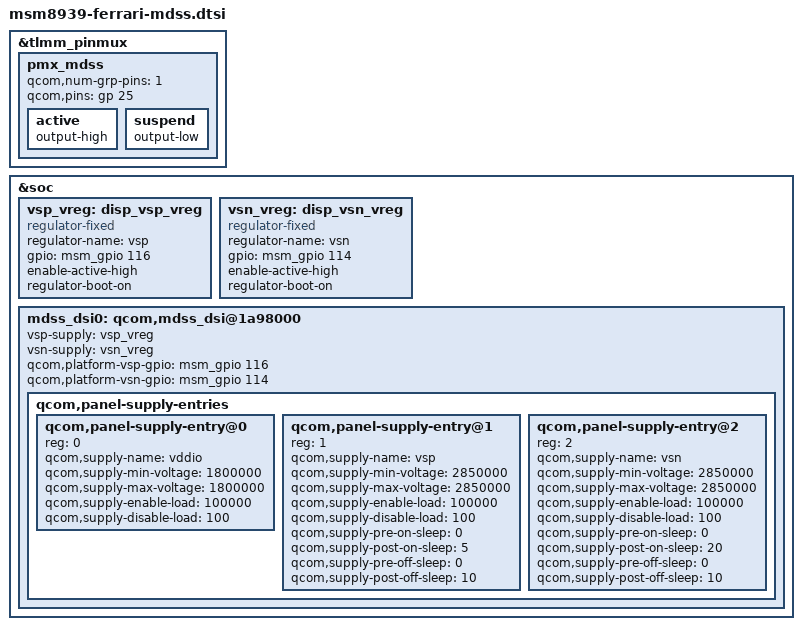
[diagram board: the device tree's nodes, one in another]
/* Copyright (c) 2014-2015, The Linux Foundation. All rights reserved.
 *
 * This program is free software; you can redistribute it and/or modify
 * it under the terms of the GNU General Public License version 2 and
 * only version 2 as published by the Free Software Foundation.
 *
 * This program is distributed in the hope that it will be useful,
 * but WITHOUT ANY WARRANTY; without even the implied warranty of
 * MERCHANTABILITY or FITNESS FOR A PARTICULAR PURPOSE.  See the
 * GNU General Public License for more details.
 */

&tlmm_pinmux {
	pmx_mdss: pmx_mdss {
		qcom,num-grp-pins = <1>;
		qcom,pins = <&gp 25>;

		/* revert ab9cf13bf5 */
		active {
			output-high;
		};
		suspend {
			output-low;
		};
	};
};

&soc {
	vsp_vreg: disp_vsp_vreg {
		compatible = "regulator-fixed";
		regulator-name = "vsp";
		gpio = <&msm_gpio 116 0>;
		enable-active-high;
		regulator-boot-on;
	};

	vsn_vreg: disp_vsn_vreg {
		compatible = "regulator-fixed";
		regulator-name = "vsn";
		gpio = <&msm_gpio 114 0>;
		enable-active-high;
		regulator-boot-on;
	};

	mdss_dsi0: qcom,mdss_dsi@1a98000 {
		/delete-property/ qcom,platform-enable-gpio;
		/delete-property/ qcom,platform-bklight-en-gpio;

		vsp-supply = <&vsp_vreg>;
		vsn-supply = <&vsn_vreg>;

		qcom,platform-vsp-gpio = <&msm_gpio 116 0>;
		qcom,platform-vsn-gpio = <&msm_gpio 114 0>;

		qcom,panel-supply-entries {
			#address-cells = <1>;
			#size-cells = <0>;
			qcom,panel-supply-entry@0 {
				reg = <0>;
				qcom,supply-name = "vddio";
				qcom,supply-min-voltage = <1800000>;
				qcom,supply-max-voltage = <1800000>;
				qcom,supply-enable-load = <100000>;
				qcom,supply-disable-load = <100>;
			};

			qcom,panel-supply-entry@1 {
				reg = <1>;
				qcom,supply-name = "vsp";
				qcom,supply-min-voltage = <2850000>;
				qcom,supply-max-voltage = <2850000>;
				qcom,supply-enable-load = <100000>;
				qcom,supply-disable-load = <100>;
				qcom,supply-pre-on-sleep = <0>;
				qcom,supply-post-on-sleep = <5>;
				qcom,supply-pre-off-sleep = <0>;
				qcom,supply-post-off-sleep = <10>;
			};

			qcom,panel-supply-entry@2 {
				reg = <2>;
				qcom,supply-name = "vsn";
				qcom,supply-min-voltage = <2850000>;
				qcom,supply-max-voltage = <2850000>;
				qcom,supply-enable-load = <100000>;
				qcom,supply-disable-load = <100>;
				qcom,supply-pre-on-sleep = <0>;
				qcom,supply-post-on-sleep = <20>;
				qcom,supply-pre-off-sleep = <0>;
				qcom,supply-post-off-sleep = <10>;
			};
		};
	};
};
